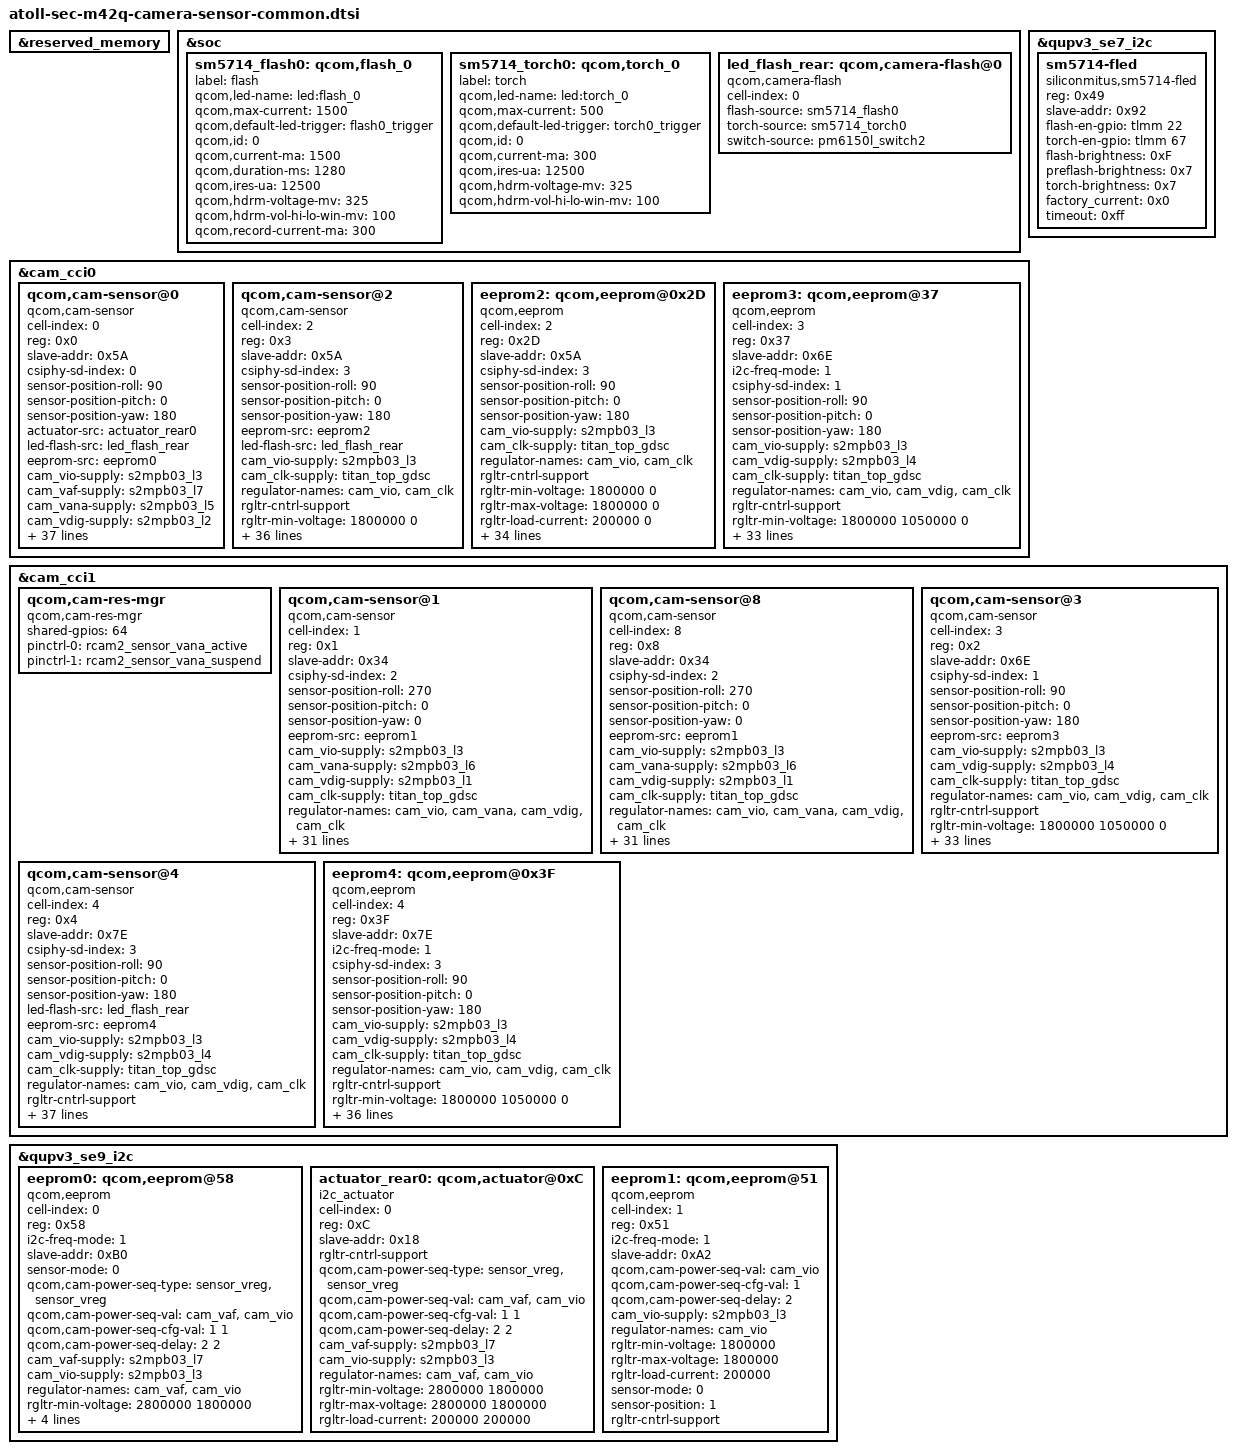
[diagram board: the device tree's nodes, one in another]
/* Copyright (c) 2020, The Linux Foundation. All rights reserved.
 *
 * This program is free software; you can redistribute it and/or modify
 * it under the terms of the GNU General Public License version 2 and
 * only version 2 as published by the Free Software Foundation.
 *
 * This program is distributed in the hope that it will be useful,
 * but WITHOUT ANY WARRANTY; without even the implied warranty of
 * MERCHANTABILITY or FITNESS FOR A PARTICULAR PURPOSE.  See the
 * GNU General Public License for more details.
 */

#include <dt-bindings/regulator/qcom,rpmh-regulator.h>
#include <dt-bindings/clock/qcom,camcc-atoll.h>

&reserved_memory {

};

&soc {
	sm5714_flash0: qcom,flash_0 {
		label = "flash";
		qcom,led-name = "led:flash_0";
		qcom,max-current = <1500>;
		qcom,default-led-trigger = "flash0_trigger";
		qcom,id = <0>;
		qcom,current-ma = <1500>;
		qcom,duration-ms = <1280>;
		qcom,ires-ua = <12500>;
		qcom,hdrm-voltage-mv = <325>;
		qcom,hdrm-vol-hi-lo-win-mv = <100>;
		qcom,record-current-ma = <300>;
	};

	sm5714_torch0: qcom,torch_0 {
		label = "torch";
		qcom,led-name = "led:torch_0";
		qcom,max-current = <500>;
		qcom,default-led-trigger = "torch0_trigger";
		qcom,id = <0>;
		qcom,current-ma = <300>;
		qcom,ires-ua = <12500>;
		qcom,hdrm-voltage-mv = <325>;
		qcom,hdrm-vol-hi-lo-win-mv = <100>;
	};

	led_flash_rear: qcom,camera-flash@0 {
		cell-index = <0>;
		compatible = "qcom,camera-flash";
		flash-source = <&sm5714_flash0>;
		torch-source = <&sm5714_torch0>;
		switch-source = <&pm6150l_switch2>;
		status = "ok";
	};

};

&qupv3_se7_i2c {
	status = "ok";

	sm5714-fled {
		compatible = "siliconmitus,sm5714-fled";
		reg = <0x49>;
		status = "okay";
		slave-addr = <0x92>;
		flash-en-gpio = <&tlmm 22 0>;
		torch-en-gpio = <&tlmm 67 0>;
		flash-brightness = <0xF>; //0x0(600mA) ~ 0xF(1350mA) : 50mA Step
		preflash-brightness = <0x7>;
		torch-brightness = <0x7>; //0x0(50mA) ~ 0x7(225mA) : 25mA Step
		factory_current = <0x0>; //0x0(300mA)
		timeout = <0xff>;
	};
};

&cam_cci0 {

	qcom,cam-sensor@0 { /* REAR CAM1 - 64MP Wide */
		cell-index = <0>;
		compatible = "qcom,cam-sensor";
		reg = <0x0>;
		slave-addr = <0x5A>;
		csiphy-sd-index = <0>;
		sensor-position-roll = <90>;
		sensor-position-pitch = <0>;
		sensor-position-yaw = <180>;

		actuator-src = <&actuator_rear0>;
		led-flash-src = <&led_flash_rear>;
		eeprom-src = <&eeprom0>;

		// LDO
		cam_vio-supply = <&s2mpb03_l3>;
		cam_vaf-supply = <&s2mpb03_l7>;
		cam_vana-supply = <&s2mpb03_l5>;
		cam_vdig-supply = <&s2mpb03_l2>;
		cam_clk-supply = <&titan_top_gdsc>;
		regulator-names = "cam_vio","cam_vaf","cam_vana","cam_vdig","cam_clk";
		rgltr-cntrl-support;
		rgltr-min-voltage = <1800000 2800000 2800000 1050000 0>;
		rgltr-max-voltage = <1800000 2800000 2800000 1050000 0>;
		rgltr-load-current = <200000 200000 200000 200000 0>;

		// GPIO
		gpio-no-mux = <0>;
		pinctrl-names = "cam_default", "cam_suspend";
		pinctrl-0 = <&cam_sensor_mclk0_active &rcam1_sensor_reset_active>;
		pinctrl-1 = <&cam_sensor_mclk0_suspend &rcam1_sensor_reset_suspend>;

		gpios = <&tlmm 13 0>,  /* MCLK */
			<&tlmm 30 0>;     /* RST */
		gpio-reset = <1>;
		gpio-req-tbl-num = <0 1>;
		gpio-req-tbl-flags = <1 0>;
		gpio-req-tbl-label = "CAMIF_MCLK0", "CAM_RESET0";

		sensor-mode = <0>;
		cci-device = <0>;
		cci-master = <0>;
		status = "ok";
		clocks = <&clock_camcc CAM_CC_MCLK0_CLK>;
		clock-names = "cam_clk";
		clock-cntl-level = "turbo";
		clock-rates = <19200000>;

		cam,isp = <0>;                  // 0 : INT , 1 : EXT , 2 : SOC
		cam,cal_memory = <2>;           // 0 : N , 1 : FROM , 2 : EEPROM , 3 : OTP
		cam,read_version = <0>;         // 0 : SYSFS , 1 : CAMON
		cam,core_voltage = <0>;         // 0 : N , 1 : Y
		cam,upgrade = <0>;              // 0 : N , 1 : SYSFS , 2 : CAMON
		cam,fw_write = <0>;             // 0 : N , 1 : OS , 2 : SD , 3 : ALL
		cam,fw_dump = <0>;              // 0 : N , 1 : Y
		cam,companion_chip = <0>;       // 0 : N , 1 : Y
		cam,ois = <0>;                  // 0 : N , 1 : Y
		cam,dual_open = <0>;            // 0 : N , 1 : Y
		cam,valid = <1>;                // 0 : N , 1 : Y
	};

	qcom,cam-sensor@2 { /* REAR CAM3 - 12MP UW */
		cell-index = <2>;
		compatible = "qcom,cam-sensor";
		reg = <0x3>;
		slave-addr = <0x5A>;
		csiphy-sd-index = <3>;
		sensor-position-roll = <90>;
		sensor-position-pitch = <0>;
		sensor-position-yaw = <180>;
		eeprom-src = <&eeprom2>;
		led-flash-src = <&led_flash_rear>;

		cam_vio-supply = <&s2mpb03_l3>;
		cam_clk-supply = <&titan_top_gdsc>;
		regulator-names =  "cam_vio", "cam_clk";
		rgltr-cntrl-support;
		rgltr-min-voltage = <1800000 0>;
		rgltr-max-voltage = <1800000 0>;
		rgltr-load-current = <200000 0>;

		gpio-no-mux = <0>;
		pinctrl-names = "cam_default", "cam_suspend";
		pinctrl-0 = <&cam_sensor_mclk3_active &rcam3_sensor_reset_active
						&rcam3_sensor_vana_active &cam_mipi_sel_active>;
		pinctrl-1 = <&cam_sensor_mclk3_suspend &rcam3_sensor_reset_suspend
						&rcam3_sensor_vana_suspend &cam_mipi_sel_suspend>;
		gpios = <&tlmm 15 0>,	/* MCLK */
				<&tlmm 29 0>,	/* RST */
				<&tlmm 65 0>,	/* VANA */
				<&tlmm 66 0>;	/* MIPI SEL */

		gpio-reset = <1>;
		gpio-vana = <2>;
		gpio-custom1 = <3>;
		gpio-req-tbl-num = <0 1 2 3>;
		gpio-req-tbl-flags = <1 0 0 0>;
		gpio-req-tbl-label = "CAMIF_MCLK2", "CAM_RESET3", "CAM_VANA3", "MIPI_SEL";

		sensor-mode = <0>;
		cci-device = <0>;
		cci-master = <1>;
		status = "ok";
		clocks = <&clock_camcc CAM_CC_MCLK2_CLK>;
		clock-names = "cam_clk";
		clock-cntl-level = "turbo";
		clock-rates = <19200000>;

		cam,isp = <0>;                  // 0 : INT , 1 : EXT , 2 : SOC
		cam,cal_memory = <2>;           // 0 : N , 1 : FROM , 2 : EEPROM , 3 : OTP
		cam,read_version = <0>;         // 0 : SYSFS , 1 : CAMON
		cam,core_voltage = <0>;         // 0 : N , 1 : Y
		cam,upgrade = <0>;              // 0 : N , 1 : SYSFS , 2 : CAMON
		cam,fw_write = <0>;             // 0 : N , 1 : OS , 2 : SD , 3 : ALL
		cam,fw_dump = <0>;              // 0 : N , 1 : Y
		cam,companion_chip = <0>;       // 0 : N , 1 : Y
		cam,ois = <0>;                  // 0 : N , 1 : Y
		cam,dual_open = <0>;            // 0 : N , 1 : Y
		cam,valid = <1>;
	};

	eeprom2: qcom,eeprom@0x2D {
		cell-index = <2>;
		compatible = "qcom,eeprom";
		reg = <0x2D>;
		slave-addr = <0x5A>;

		csiphy-sd-index = <3>;
		sensor-position-roll = <90>;
		sensor-position-pitch = <0>;
		sensor-position-yaw = <180>;

		cam_vio-supply = <&s2mpb03_l3>;
		cam_clk-supply = <&titan_top_gdsc>;
		regulator-names =  "cam_vio", "cam_clk";
		rgltr-cntrl-support;
		rgltr-min-voltage = <1800000 0>;
		rgltr-max-voltage = <1800000 0>;
		rgltr-load-current = <200000 0>;

		gpio-no-mux = <0>;
		pinctrl-names = "cam_default", "cam_suspend";
		pinctrl-0 = <&cam_sensor_mclk3_active &rcam3_sensor_reset_active &rcam3_sensor_vana_active &cam_mipi_sel_active>;
		pinctrl-1 = <&cam_sensor_mclk3_suspend &rcam3_sensor_reset_suspend &rcam3_sensor_vana_suspend &cam_mipi_sel_suspend>;
		gpios = <&tlmm 15 0>, /* MCLK */
			<&tlmm 29 0>,     /* RST */
			<&tlmm 65 0>, /* VANA */
			<&tlmm 66 0>; /*MIPI SEL*/

		gpio-reset = <1>;
		gpio-vana = <2>;
		gpio-custom1 = <3>;
		gpio-req-tbl-num = <0 1 2 3>;
		gpio-req-tbl-flags = <1 0 0 0>;
		gpio-req-tbl-label = "CAMIF_MCLK2", "CAM_RESET3", "CAM_VANA3", "MIPI_SEL";

		sensor-mode = <0>;
		cci-device = <0>;
		cci-master = <1>;
		status = "ok";
		clocks = <&clock_camcc CAM_CC_MCLK2_CLK>;
		clock-names = "cam_clk";
		clock-cntl-level = "turbo";
		clock-rates = <19200000>;

		cam,isp = <0>;                  // 0 : INT , 1 : EXT , 2 : SOC
		cam,cal_memory = <2>;           // 0 : N , 1 : FROM , 2 : EEPROM , 3 : OTP
		cam,read_version = <0>;         // 0 : SYSFS , 1 : CAMON
		cam,core_voltage = <0>;         // 0 : N , 1 : Y
		cam,upgrade = <0>;              // 0 : N , 1 : SYSFS , 2 : CAMON
		cam,fw_write = <0>;             // 0 : N , 1 : OS , 2 : SD , 3 : ALL
		cam,fw_dump = <0>;              // 0 : N , 1 : Y
		cam,companion_chip = <0>;       // 0 : N , 1 : Y
		cam,ois = <0>;                  // 0 : N , 1 : Y
		cam,dual_open = <0>;            // 0 : N , 1 : Y
		cam,valid = <1>;
	};

	eeprom3: qcom,eeprom@37 {
		cell-index = <3>;
		compatible = "qcom,eeprom";
		reg = <0x37>;
		slave-addr = <0x6E>;
		i2c-freq-mode = <1>;

		csiphy-sd-index = <1>;
		sensor-position-roll = <90>;
		sensor-position-pitch = <0>;
		sensor-position-yaw = <180>;

		// LDO
		cam_vio-supply = <&s2mpb03_l3>;
		cam_vdig-supply = <&s2mpb03_l4>;
		cam_clk-supply = <&titan_top_gdsc>;
		regulator-names = "cam_vio", "cam_vdig", "cam_clk";
		rgltr-cntrl-support;
		rgltr-min-voltage = <1800000 1050000 0>;
		rgltr-max-voltage = <1800000 1050000 0>;
		rgltr-load-current = <200000 200000 0>;

		// GPIO
		gpio-no-mux = <0>;
		pinctrl-names = "cam_default", "cam_suspend";
		pinctrl-0 = <&cam_sensor_mclk2_active &rcam2_sensor_reset_active &rcam2_sensor_vana_active>;
		pinctrl-1 = <&cam_sensor_mclk2_suspend &rcam2_sensor_reset_suspend &rcam2_sensor_vana_suspend>;

		gpios = <&tlmm 14 0>,  /* MCLK */
			<&tlmm 42 0>,  /* RST */
			<&tlmm 64 0>;  /* VANA */

		gpio-reset = <1>;
		gpio-vana = <2>;
		gpio-req-tbl-num = <0 1 2>;
		gpio-req-tbl-flags = <1 0 0>;
		gpio-req-tbl-label = "CAMIF_MCLK1", "CAM_RESET2", "CAM_VANA2";

		sensor-mode = <0>;
		cci-device = <1>;
		cci-master = <0>;
		status = "ok";
		clocks = <&clock_camcc CAM_CC_MCLK1_CLK>;
		clock-names = "cam_clk";
		clock-cntl-level = "turbo";
		clock-rates = <24000000>;

		cam,isp = <0>;                  // 0 : INT , 1 : EXT , 2 : SOC
		cam,cal_memory = <0>;           // 0 : N , 1 : FROM , 2 : EEPROM , 3 : OTP
		cam,read_version = <0>;         // 0 : SYSFS , 1 : CAMON
		cam,core_voltage = <0>;         // 0 : N , 1 : Y
		cam,upgrade = <0>;              // 0 : N , 1 : SYSFS , 2 : CAMON
		cam,fw_write = <0>;             // 0 : N , 1 : OS , 2 : SD , 3 : ALL
		cam,fw_dump = <0>;              // 0 : N , 1 : Y
		cam,companion_chip = <0>;       // 0 : N , 1 : Y
		cam,ois = <0>;                  // 0 : N , 1 : Y
		cam,dual_open = <0>;            // 0 : N , 1 : Y
		cam,valid = <1>;                // 0 : N , 1 : Y
	};

};

&cam_cci1 {

	qcom,cam-res-mgr {
		compatible = "qcom,cam-res-mgr";
		shared-gpios = <64>;
		pinctrl-names = "cam_res_mgr_default", "cam_res_mgr_suspend";
		status = "ok";
		pinctrl-0 = <&rcam2_sensor_vana_active>;
		pinctrl-1 = <&rcam2_sensor_vana_suspend>;
	};

	qcom,cam-sensor@1 {   /* VT 32M */
		cell-index = <1>;
		compatible = "qcom,cam-sensor";
		reg = <0x1>;
		slave-addr = <0x34>;
		csiphy-sd-index = <2>;
		sensor-position-roll = <270>;
		sensor-position-pitch = <0>;
		sensor-position-yaw = <0>;

		eeprom-src = <&eeprom1>;

		// LDO
		cam_vio-supply = <&s2mpb03_l3>;
		cam_vana-supply = <&s2mpb03_l6>;
		cam_vdig-supply = <&s2mpb03_l1>;
		cam_clk-supply = <&titan_top_gdsc>;
		regulator-names = "cam_vio", "cam_vana", "cam_vdig", "cam_clk";
		rgltr-cntrl-support;
		rgltr-min-voltage = <1800000 2900000 1050000 0>;
		rgltr-max-voltage = <1800000 2900000 1050000 0>;
		rgltr-load-current = <200000 200000 200000 0>;

		// GPIO
		gpio-no-mux = <0>;
		pinctrl-names = "cam_default", "cam_suspend";
		pinctrl-0 = <&cam_sensor_mclk1_active &front_sensor_reset_active>;
		pinctrl-1 = <&cam_sensor_mclk1_suspend &front_sensor_reset_suspend >;

		gpios = <&tlmm 23 0>,  /* MCLK */
			<&tlmm 21 0>;   /*RST */

		gpio-reset = <1>;
		gpio-req-tbl-num = <0 1>;
		gpio-req-tbl-flags = <1 0>;
		gpio-req-tbl-label = "CAMIF_MCLK4", "CAM_RESET1";

		sensor-mode = <0>;
		cci-device = <1>;
		cci-master = <0>;
		status = "ok";
		clocks = <&clock_camcc CAM_CC_MCLK4_CLK>;
		clock-names = "cam_clk";
		clock-cntl-level = "turbo";
		clock-rates = <24000000>;

		cam,isp = <0>;                  // 0 : INT , 1 : EXT , 2 : SOC
		cam,cal_memory = <2>;           // 0 : N , 1 : FROM , 2 : EEPROM , 3 : OTP
		cam,read_version = <0>;         // 0 : SYSFS , 1 : CAMON
		cam,core_voltage = <0>;         // 0 : N , 1 : Y
		cam,upgrade = <0>;              // 0 : N , 1 : SYSFS , 2 : CAMON
		cam,fw_write = <0>;             // 0 : N , 1 : OS , 2 : SD , 3 : ALL
		cam,fw_dump = <0>;              // 0 : N , 1 : Y
		cam,companion_chip = <0>;       // 0 : N , 1 : Y
		cam,ois = <0>;                  // 0 : N , 1 : Y
		cam,dual_open = <0>;            // 0 : N , 1 : Y
		cam,valid = <1>;                // 0 : N , 1 : Y
	};

	qcom,cam-sensor@8 {   /* VT 32M */
		cell-index = <8>;
		compatible = "qcom,cam-sensor";
		reg = <0x8>;
		slave-addr = <0x34>;
		csiphy-sd-index = <2>;
		sensor-position-roll = <270>;
		sensor-position-pitch = <0>;
		sensor-position-yaw = <0>;

		eeprom-src = <&eeprom1>;

		// LDO
		cam_vio-supply = <&s2mpb03_l3>;
		cam_vana-supply = <&s2mpb03_l6>;
		cam_vdig-supply = <&s2mpb03_l1>;
		cam_clk-supply = <&titan_top_gdsc>;
		regulator-names = "cam_vio", "cam_vana", "cam_vdig", "cam_clk";
		rgltr-cntrl-support;
		rgltr-min-voltage = <1800000 2900000 1050000 0>;
		rgltr-max-voltage = <1800000 2900000 1050000 0>;
		rgltr-load-current = <200000 200000 200000 0>;

		// GPIO
		gpio-no-mux = <0>;
		pinctrl-names = "cam_default", "cam_suspend";
		pinctrl-0 = <&cam_sensor_mclk1_active &front_sensor_reset_active>;
		pinctrl-1 = <&cam_sensor_mclk1_suspend &front_sensor_reset_suspend >;

		gpios = <&tlmm 23 0>,  /* MCLK */
			<&tlmm 21 0>;   /*RST */

		gpio-reset = <1>;
		gpio-req-tbl-num = <0 1>;
		gpio-req-tbl-flags = <1 0>;
		gpio-req-tbl-label = "CAMIF_MCLK4", "CAM_RESET1";

		sensor-mode = <0>;
		cci-device = <1>;
		cci-master = <0>;
		status = "ok";
		clocks = <&clock_camcc CAM_CC_MCLK4_CLK>;
		clock-names = "cam_clk";
		clock-cntl-level = "turbo";
		clock-rates = <24000000>;

		cam,isp = <0>;                  // 0 : INT , 1 : EXT , 2 : SOC
		cam,cal_memory = <2>;           // 0 : N , 1 : FROM , 2 : EEPROM , 3 : OTP
		cam,read_version = <0>;         // 0 : SYSFS , 1 : CAMON
		cam,core_voltage = <0>;         // 0 : N , 1 : Y
		cam,upgrade = <0>;              // 0 : N , 1 : SYSFS , 2 : CAMON
		cam,fw_write = <0>;             // 0 : N , 1 : OS , 2 : SD , 3 : ALL
		cam,fw_dump = <0>;              // 0 : N , 1 : Y
		cam,companion_chip = <0>;       // 0 : N , 1 : Y
		cam,ois = <0>;                  // 0 : N , 1 : Y
		cam,dual_open = <0>;            // 0 : N , 1 : Y
		cam,valid = <1>;                // 0 : N , 1 : Y
	};

	qcom,cam-sensor@3 {  /* REAR CAM 2 - 5M Bokeh */
		cell-index = <3>;
		compatible = "qcom,cam-sensor";
		reg = <0x2>;
		slave-addr = <0x6E>;
		csiphy-sd-index = <1>;
		sensor-position-roll = <90>;
		sensor-position-pitch = <0>;
		sensor-position-yaw = <180>;
		eeprom-src = <&eeprom3>;

		// LDO
		cam_vio-supply = <&s2mpb03_l3>;
		cam_vdig-supply = <&s2mpb03_l4>;
		cam_clk-supply = <&titan_top_gdsc>;
		regulator-names = "cam_vio", "cam_vdig", "cam_clk";
		rgltr-cntrl-support;
		rgltr-min-voltage = <1800000 1050000 0>;
		rgltr-max-voltage = <1800000 1050000 0>;
		rgltr-load-current = <200000 200000 0>;

		// GPIO
		gpio-no-mux = <0>;
		pinctrl-names = "cam_default", "cam_suspend";
		pinctrl-0 = <&cam_sensor_mclk2_active &rcam2_sensor_reset_active &rcam2_sensor_vana_active>;
		pinctrl-1 = <&cam_sensor_mclk2_suspend &rcam2_sensor_reset_suspend &rcam2_sensor_vana_suspend>;

		gpios = <&tlmm 14 0>,  /* MCLK */
			<&tlmm 42 0>,      /* RST */
			<&tlmm 64 0>;      /* VANA */

		gpio-reset = <1>;
		gpio-vana = <2>;
		gpio-req-tbl-num = <0 1 2>;
		gpio-req-tbl-flags = <1 0 0>;
		gpio-req-tbl-label = "CAMIF_MCLK1", "CAM_RESET2", "CAM_VANA2";

		sensor-mode = <0>;
		cci-device = <1>;
		cci-master = <0>;
		status = "ok";
		clocks = <&clock_camcc CAM_CC_MCLK1_CLK>;
		clock-names = "cam_clk";
		clock-cntl-level = "turbo";
		clock-rates = <24000000>;

		cam,isp = <0>;                  // 0 : INT , 1 : EXT , 2 : SOC
		cam,cal_memory = <0>;           // 0 : N , 1 : FROM , 2 : EEPROM , 3 : OTP
		cam,read_version = <0>;         // 0 : SYSFS , 1 : CAMON
		cam,core_voltage = <0>;         // 0 : N , 1 : Y
		cam,upgrade = <0>;              // 0 : N , 1 : SYSFS , 2 : CAMON
		cam,fw_write = <0>;             // 0 : N , 1 : OS , 2 : SD , 3 : ALL
		cam,fw_dump = <0>;              // 0 : N , 1 : Y
		cam,companion_chip = <0>;       // 0 : N , 1 : Y
		cam,ois = <0>;                  // 0 : N , 1 : Y
		cam,dual_open = <0>;            // 0 : N , 1 : Y
		cam,valid = <1>;                // 0 : N , 1 : Y
	};

	qcom,cam-sensor@4 {  /* REAR CAM 4 - 5M Macro  */
		cell-index = <4>;
		compatible = "qcom,cam-sensor";
		reg = <0x4>;
		slave-addr = <0x7E>;
		csiphy-sd-index = <3>;
		sensor-position-roll = <90>;
		sensor-position-pitch = <0>;
		sensor-position-yaw = <180>;
		led-flash-src = <&led_flash_rear>;
		eeprom-src = <&eeprom4>;

		// LDO
		cam_vio-supply = <&s2mpb03_l3>;
		cam_vdig-supply = <&s2mpb03_l4>;
		cam_clk-supply = <&titan_top_gdsc>;
		regulator-names = "cam_vio", "cam_vdig", "cam_clk";
		rgltr-cntrl-support;
		rgltr-min-voltage = <1800000 1050000 0>;
		rgltr-max-voltage = <1800000 1050000 0>;
		rgltr-load-current = <200000 200000 0>;

		// GPIO
		gpio-no-mux = <0>;
		pinctrl-names = "cam_default", "cam_suspend";
		pinctrl-0 = <&cam_sensor_mclk4_active &rcam4_sensor_reset_active
						&rcam2_sensor_vana_active &cam_mipi_sel_active>;
		pinctrl-1 = <&cam_sensor_mclk4_suspend &rcam4_sensor_reset_suspend
						&rcam2_sensor_vana_suspend &cam_mipi_sel_suspend>;

		gpios = <&tlmm 16 0>, /* MCLK */
			<&tlmm 24 0>, /* RESET */
			<&tlmm 64 0>, /* VANA */
			<&tlmm 66 0>; /*MIPI SEL*/

		gpio-reset = <1>;
		gpio-vana = <2>;
		gpio-custom1 = <3>;
		gpio-req-tbl-num = <0 1 2 3>;
		gpio-req-tbl-flags = <1 0 0 0>;
		gpio-req-tbl-label = "CAMIF_MCLK3", "CAM_RESET4", "CAM_VANA4", "MIPI_SEL";

		sensor-mode = <0>;
		cci-device = <1>;
		cci-master = <0>;
		status = "ok";
		clocks = <&clock_camcc CAM_CC_MCLK3_CLK>;
		clock-names = "cam_clk";
		clock-cntl-level = "turbo";
		clock-rates = <24000000>;

		cam,isp = <0>;                  // 0 : INT , 1 : EXT , 2 : SOC
		cam,cal_memory = <0>;           // 0 : N , 1 : FROM , 2 : EEPROM , 3 : OTP
		cam,read_version = <0>;         // 0 : SYSFS , 1 : CAMON
		cam,core_voltage = <0>;         // 0 : N , 1 : Y
		cam,upgrade = <0>;              // 0 : N , 1 : SYSFS , 2 : CAMON
		cam,fw_write = <0>;             // 0 : N , 1 : OS , 2 : SD , 3 : ALL
		cam,fw_dump = <0>;              // 0 : N , 1 : Y
		cam,companion_chip = <0>;       // 0 : N , 1 : Y
		cam,ois = <0>;                  // 0 : N , 1 : Y
		cam,dual_open = <0>;            // 0 : N , 1 : Y
		cam,valid = <1>;                // 0 : N , 1 : Y
	};

	eeprom4: qcom,eeprom@0x3F {
		cell-index = <4>;
		compatible = "qcom,eeprom";
		reg = <0x3F>;
		slave-addr = <0x7E>;
		i2c-freq-mode = <1>;

		csiphy-sd-index = <3>;
		sensor-position-roll = <90>;
		sensor-position-pitch = <0>;
		sensor-position-yaw = <180>;

		// LDO
		cam_vio-supply = <&s2mpb03_l3>;
		cam_vdig-supply = <&s2mpb03_l4>;
		cam_clk-supply = <&titan_top_gdsc>;
		regulator-names = "cam_vio", "cam_vdig", "cam_clk";
		rgltr-cntrl-support;
		rgltr-min-voltage = <1800000 1050000 0>;
		rgltr-max-voltage = <1800000 1050000 0>;
		rgltr-load-current = <200000 200000 0>;

		// GPIO
		gpio-no-mux = <0>;
		pinctrl-names = "cam_default", "cam_suspend";
		pinctrl-0 = <&cam_sensor_mclk4_active &rcam4_sensor_reset_active &rcam2_sensor_vana_active &cam_mipi_sel_active>;
		pinctrl-1 = <&cam_sensor_mclk4_suspend &rcam4_sensor_reset_suspend &rcam2_sensor_vana_suspend &cam_mipi_sel_suspend>;

		gpios = <&tlmm 16 0>, // MCLK
			<&tlmm 24 0>, // RESET
			<&tlmm 64 0>, // VANA
			<&tlmm 66 0>; // MIPI SEL

		gpio-reset = <1>;
		gpio-vana = <2>;
		gpio-custom1 = <3>;
		gpio-req-tbl-num = <0 1 2 3>;
		gpio-req-tbl-flags = <1 0 0 0>;
		gpio-req-tbl-label = "CAMIF_MCLK3", "CAM_RESET4", "CAM_VANA4", "MIPI_SEL";

		sensor-mode = <0>;
		cci-device = <1>;
		cci-master = <0>;
		status = "ok";
		clocks = <&clock_camcc CAM_CC_MCLK3_CLK>;
		clock-names = "cam_clk";
		clock-cntl-level = "turbo";
		clock-rates = <24000000>;

		cam,isp = <0>;                  // 0 : INT , 1 : EXT , 2 : SOC
		cam,cal_memory = <0>;           // 0 : N , 1 : FROM , 2 : EEPROM , 3 : OTP
		cam,read_version = <0>;         // 0 : SYSFS , 1 : CAMON
		cam,core_voltage = <0>;         // 0 : N , 1 : Y
		cam,upgrade = <0>;              // 0 : N , 1 : SYSFS , 2 : CAMON
		cam,fw_write = <0>;             // 0 : N , 1 : OS , 2 : SD , 3 : ALL
		cam,fw_dump = <0>;              // 0 : N , 1 : Y
		cam,companion_chip = <0>;       // 0 : N , 1 : Y
		cam,ois = <0>;                  // 0 : N , 1 : Y
		cam,dual_open = <0>;            // 0 : N , 1 : Y
		cam,valid = <1>;                // 0 : N , 1 : Y
	};

};

&qupv3_se9_i2c {

	eeprom0: qcom,eeprom@58 {
		cell-index = <0>;
		reg = <0x58>;
		compatible = "qcom,eeprom";
		i2c-freq-mode = <1>;
		slave-addr = <0xB0>;
		sensor-mode = <0>;

		qcom,cam-power-seq-type = "sensor_vreg", "sensor_vreg";
		qcom,cam-power-seq-val = "cam_vaf", "cam_vio";
		qcom,cam-power-seq-cfg-val = <1 1>;
		qcom,cam-power-seq-delay = <2 2>;

		cam_vaf-supply = <&s2mpb03_l7>;
		cam_vio-supply = <&s2mpb03_l3>;

		regulator-names = "cam_vaf","cam_vio";
		rgltr-min-voltage = <2800000 1800000>;
		rgltr-max-voltage = <2800000 1800000>;
		rgltr-load-current = <200000 200000>;

		sensor-position = <0>;
		rgltr-cntrl-support;
	};

	actuator_rear0: qcom,actuator@0xC {
		cell-index = <0>;
		reg = <0xC>;
		slave-addr = <0x18>;
		compatible = "i2c_actuator";

                rgltr-cntrl-support;
		qcom,cam-power-seq-type = "sensor_vreg", "sensor_vreg";
		qcom,cam-power-seq-val = "cam_vaf", "cam_vio";
		qcom,cam-power-seq-cfg-val = <1 1>;
		qcom,cam-power-seq-delay = <2 2>;

		cam_vaf-supply = <&s2mpb03_l7>;
		cam_vio-supply = <&s2mpb03_l3>;

		regulator-names = "cam_vaf","cam_vio";
		rgltr-min-voltage = <2800000 1800000>;
		rgltr-max-voltage = <2800000 1800000>;
		rgltr-load-current = <200000 200000>;

	};

	eeprom1: qcom,eeprom@51 {
		cell-index = <1>;
		reg = <0x51>;
		compatible = "qcom,eeprom";
		i2c-freq-mode = <1>;
		slave-addr = <0xA2>;

		qcom,cam-power-seq-val = "cam_vio";
		qcom,cam-power-seq-cfg-val = <1>;
		qcom,cam-power-seq-delay = <2>;

		cam_vio-supply = <&s2mpb03_l3>;
		regulator-names = "cam_vio";
		rgltr-min-voltage = <1800000>;
		rgltr-max-voltage = <1800000>;
		rgltr-load-current = <200000>;

		sensor-mode = <0>;
		sensor-position = <1>;
		rgltr-cntrl-support;
	};

};
